# gpio register map
Vendor: Texas Instruments
Peripheral module from a debugger description file (folder Keystone2).
Registers are 32-bit, read-write, no defined reset value unless marked. A register's access mark holds for its fields unless they carry their own. Offsets are as the file gives them; lines under a group give offsets from that group; [hi:lo] are bit positions; {n}, {i} and the like mark numbered series; 'fields as' and 'values as' point back to an identical list; <NAME> marks a mode.

## GPIO
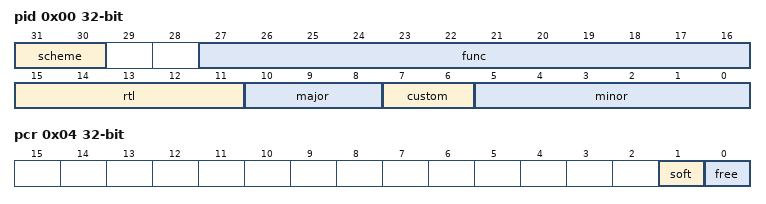
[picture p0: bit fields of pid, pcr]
0x00 pid
  [31:30] scheme, [27:16] func, [15:11] rtl, [10:8] major, [7:6] custom, [5:0] minor
0x04 pcr
  [1] soft, [0] free
0x08 binten
  [7:0] en
0x10 bank_registers_dir — (1 of 4, stride 40)
  [15:0] dir
0x14 bank_registers_out_data — (1 of 4, stride 40)
  [15:0] out
0x18 bank_registers_set_data — (1 of 4, stride 40)
  [15:0] set
0x1C bank_registers_clr_data — (1 of 4, stride 40)
  [15:0] clr
0x20 bank_registers_in_data — (1 of 4, stride 40)
  [15:0] in
0x24 bank_registers_set_ris_trig — (1 of 4, stride 40)
  [15:0] setris
0x28 bank_registers_clr_ris_trig — (1 of 4, stride 40)
  [15:0] clrris
0x2C bank_registers_set_fal_trig — (1 of 4, stride 40)
  [15:0] setfal
0x30 bank_registers_clr_fal_trig — (1 of 4, stride 40)
  [15:0] clrfal
0x34 bank_registers_intstat — (1 of 4, stride 40)
  [15:0] stat
